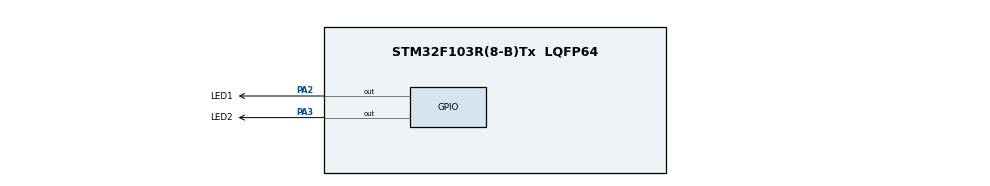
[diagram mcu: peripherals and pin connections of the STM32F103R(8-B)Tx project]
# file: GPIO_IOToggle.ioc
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Mcu.Family=STM32F1
Mcu.Name=STM32F103R(8-B)Tx
Mcu.Package=LQFP64
NVIC.PriorityGroup=NVIC_PRIORITYGROUP_4
PA13.Mode=Serial_Wire
PA13.Signal=SYS_JTMS-SWDIO
PA14.Mode=Serial_Wire
PA14.Signal=SYS_JTCK-SWCLK
PA2.GPIO_Label=LED1
PA2.Signal=GPIO_Output
PA3.GPIO_Label=LED2
PA3.Signal=GPIO_Output
PD0-OSC_IN.Mode=HSE-External-Oscillator
PD0-OSC_IN.Signal=RCC_OSC_IN
PD1-OSC_OUT.Mode=HSE-External-Oscillator
PD1-OSC_OUT.Signal=RCC_OSC_OUT
ProjectManager.HeapSize=0x200
ProjectManager.StackSize=0x400
ProjectManager.TargetToolchain=MDK-ARM V4
RCC.APB1Freq_Value=8000000
RCC.APB2Freq_Value=8000000
RCC.SYSCLKSource=RCC_SYSCLKSOURCE_HSE
board=GPIO_IOToggle

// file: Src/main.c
/**
  ******************************************************************************
  * File Name          : main.c
  * Description        : Main program body
  ******************************************************************************
  *
  * COPYRIGHT(c) 2016 STMicroelectronics
  *
  * Redistribution and use in source and binary forms, with or without modification,
  * are permitted provided that the following conditions are met:
  *   1. Redistributions of source code must retain the above copyright notice,
  *      this list of conditions and the following disclaimer.
  *   2. Redistributions in binary form must reproduce the above copyright notice,
  *      this list of conditions and the following disclaimer in the documentation
  *      and/or other materials provided with the distribution.
  *   3. Neither the name of STMicroelectronics nor the names of its contributors
  *      may be used to endorse or promote products derived from this software
  *      without specific prior written permission.
  *
  * THIS SOFTWARE IS PROVIDED BY THE COPYRIGHT HOLDERS AND CONTRIBUTORS "AS IS"
  * AND ANY EXPRESS OR IMPLIED WARRANTIES, INCLUDING, BUT NOT LIMITED TO, THE
  * IMPLIED WARRANTIES OF MERCHANTABILITY AND FITNESS FOR A PARTICULAR PURPOSE ARE
  * DISCLAIMED. IN NO EVENT SHALL THE COPYRIGHT HOLDER OR CONTRIBUTORS BE LIABLE
  * FOR ANY DIRECT, INDIRECT, INCIDENTAL, SPECIAL, EXEMPLARY, OR CONSEQUENTIAL
  * DAMAGES (INCLUDING, BUT NOT LIMITED TO, PROCUREMENT OF SUBSTITUTE GOODS OR
  * SERVICES; LOSS OF USE, DATA, OR PROFITS; OR BUSINESS INTERRUPTION) HOWEVER
  * CAUSED AND ON ANY THEORY OF LIABILITY, WHETHER IN CONTRACT, STRICT LIABILITY,
  * OR TORT (INCLUDING NEGLIGENCE OR OTHERWISE) ARISING IN ANY WAY OUT OF THE USE
  * OF THIS SOFTWARE, EVEN IF ADVISED OF THE POSSIBILITY OF SUCH DAMAGE.
  *
  ******************************************************************************
  */
#include "main.h"
#include "stm32f1xx_hal.h"
#include "gpio.h"

/* USER CODE BEGIN PV */
/* Private variables ---------------------------------------------------------*/

/* USER CODE END PV */

void SystemClock_Config(void);
void Error_Handler(void);

/* USER CODE BEGIN PFP */
/* Private function prototypes -----------------------------------------------*/

/* USER CODE END PFP */

int main(void)
{

  /* MCU Configuration----------------------------------------------------------*/

  /* Reset of all peripherals, Initializes the Flash interface and the Systick. */
  HAL_Init();

  /* Configure the system clock */
  SystemClock_Config();

  /* Initialize all configured peripherals */
  MX_GPIO_Init();

  /* Infinite loop */
  while (1)
  {

  /* USER CODE BEGIN 3 */
		HAL_GPIO_WritePin(LED1_GPIO_Port, LED1_Pin, GPIO_PIN_SET);
		HAL_GPIO_WritePin(LED2_GPIO_Port, LED2_Pin, GPIO_PIN_RESET);
		HAL_Delay(500);
		HAL_GPIO_WritePin(LED1_GPIO_Port, LED1_Pin, GPIO_PIN_RESET);
		HAL_GPIO_WritePin(LED2_GPIO_Port, LED2_Pin, GPIO_PIN_SET);
		HAL_Delay(500);
  }
  /* USER CODE END 3 */

}

/** System Clock Configuration
*/
void SystemClock_Config(void)
{

  RCC_OscInitTypeDef RCC_OscInitStruct;
  RCC_ClkInitTypeDef RCC_ClkInitStruct;

    /**Initializes the CPU, AHB and APB busses clocks
    */
  RCC_OscInitStruct.OscillatorType = RCC_OSCILLATORTYPE_HSE;
  RCC_OscInitStruct.HSEState = RCC_HSE_ON;
  RCC_OscInitStruct.PLL.PLLState = RCC_PLL_NONE;
  if (HAL_RCC_OscConfig(&RCC_OscInitStruct) != HAL_OK)
  {
    Error_Handler();
  }

    /**Initializes the CPU, AHB and APB busses clocks
    */
  RCC_ClkInitStruct.ClockType = RCC_CLOCKTYPE_HCLK|RCC_CLOCKTYPE_SYSCLK
                              |RCC_CLOCKTYPE_PCLK1|RCC_CLOCKTYPE_PCLK2;
  RCC_ClkInitStruct.SYSCLKSource = RCC_SYSCLKSOURCE_HSE;
  RCC_ClkInitStruct.AHBCLKDivider = RCC_SYSCLK_DIV1;
  RCC_ClkInitStruct.APB1CLKDivider = RCC_HCLK_DIV1;
  RCC_ClkInitStruct.APB2CLKDivider = RCC_HCLK_DIV1;

  if (HAL_RCC_ClockConfig(&RCC_ClkInitStruct, FLASH_LATENCY_0) != HAL_OK)
  {
    Error_Handler();
  }

    /**Configure the Systick interrupt time
    */
  HAL_SYSTICK_Config(HAL_RCC_GetHCLKFreq()/1000);

    /**Configure the Systick
    */
  HAL_SYSTICK_CLKSourceConfig(SYSTICK_CLKSOURCE_HCLK);

  /* SysTick_IRQn interrupt configuration */
  HAL_NVIC_SetPriority(SysTick_IRQn, 0, 0);
}

void Error_Handler(void)
{
  while(1)
  {
  }
}

/************************ (C) COPYRIGHT STMicroelectronics *****END OF FILE****/
